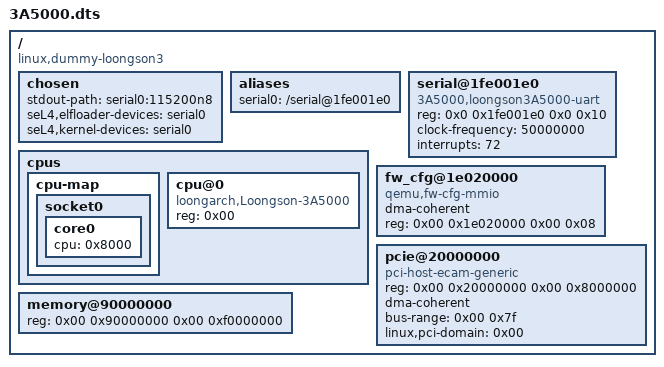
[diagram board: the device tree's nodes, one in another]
/*
 * Copyright 2022, tyyteam(Qingtao Liu, Yang Lei, Yang Chen)
 * qtliu@mail.ustc.edu.cn, le24@mail.ustc.edu.cn, chenyangcs@mail.ustc.edu.cn
 * 
 * Derived from:
 * Copyright Linux Kernel Team
 * SPDX-License-Identifier: GPL-2.0-only
 *
 * This file is derived from an intermediate build stage of the
 * Linux kernel. The licenses of all input files to this process
 * are compatible with GPL-2.0-only.
 */

/dts-v1/;

/ {
  #address-cells = <0x00000002>;
  #size-cells = <0x00000002>;
  compatible = "linux,dummy-loongson3";

  chosen {
    stdout-path = "serial0:115200n8";    
    seL4,elfloader-devices ="serial0";
		seL4,kernel-devices ="serial0";
  };

  aliases {
		serial0 = "/serial@1fe001e0";
  };


  serial@1fe001e0 {
    device_type = "serial";
    compatible = "3A5000,loongson3A5000-uart";
    reg = < 0x0 0x1fe001e0 0x0 0x10 >;
    clock-frequency = < 50000000 >;
    interrupts = < 72 >;
    status = "okay";
    pinctrl-names = "default";
  };


	cpus {
		#size-cells = <0x00>;
		#address-cells = <0x01>;

		cpu-map {

			socket0 {

				core0 {
					cpu = <0x8000>;
				};
			};
		};

		cpu@0 {
			phandle = <0x8000>;
			reg = <0x00>;
			compatible = "loongarch,Loongson-3A5000";
			device_type = "cpu";
		};
	};

  fw_cfg@1e020000 {
		dma-coherent;
		reg = <0x00 0x1e020000 0x00 0x08>;
		compatible = "qemu,fw-cfg-mmio";
	};

  pcie@20000000 {
		ranges = <0x1000000 0x00 0x4000 0x00 0x18004000 0x00 0xc000 0x2000000 0x00 0x40000000 0x00 0x40000000 0x00 0x40000000>;
		reg = <0x00 0x20000000 0x00 0x8000000>;
		dma-coherent;
		bus-range = <0x00 0x7f>;
		linux,pci-domain = <0x00>;
		#size-cells = <0x02>;
		#address-cells = <0x03>;
		device_type = "pci";
		compatible = "pci-host-ecam-generic";
	};

  memory@90000000 {
    device_type = "memory";
    reg = <0x00 0x90000000 0x00 0xf0000000>;       
  };

};
